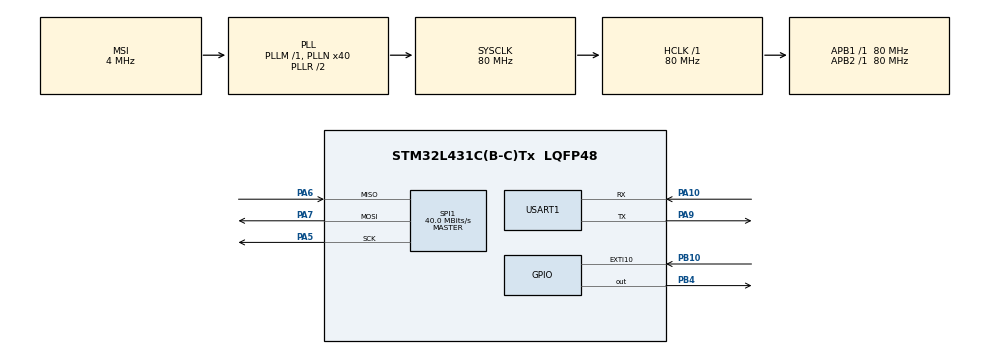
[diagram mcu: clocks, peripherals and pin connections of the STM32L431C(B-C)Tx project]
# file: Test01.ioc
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FREERTOS.Tasks01=defaultTask,24,128,StartDefaultTask,Default,NULL,Dynamic,NULL,NULL
Mcu.Family=STM32L4
Mcu.Name=STM32L431C(B-C)Tx
Mcu.Package=LQFP48
NVIC.EXTI15_10_IRQn=true\:5\:0\:false\:false\:true\:true\:true\:true\:true
NVIC.PriorityGroup=NVIC_PRIORITYGROUP_4
NVIC.SPI1_IRQn=true\:5\:0\:false\:false\:true\:true\:true\:true\:true
NVIC.TIM7_IRQn=true\:15\:0\:false\:false\:true\:false\:false\:true\:true
NVIC.TimeBase=TIM7_IRQn
NVIC.TimeBaseIP=TIM7
PA10.Mode=Asynchronous
PA10.Signal=USART1_RX
PA5.Mode=Full_Duplex_Master
PA5.Signal=SPI1_SCK
PA6.Mode=Full_Duplex_Master
PA6.Signal=SPI1_MISO
PA7.Mode=Full_Duplex_Master
PA7.Signal=SPI1_MOSI
PA9.Mode=Asynchronous
PA9.Signal=USART1_TX
PB0.Signal=SPI1_NSS
PB10.Signal=GPXTI10
PB4\ (NJTRST).Signal=GPIO_Output
ProjectManager.HeapSize=0x200
ProjectManager.StackSize=0x400
ProjectManager.TargetToolchain=Makefile
RCC.AHBFreq_Value=80000000
RCC.APB1Freq_Value=80000000
RCC.APB1TimFreq_Value=80000000
RCC.APB2Freq_Value=80000000
RCC.APB2TimFreq_Value=80000000
RCC.CortexFreq_Value=80000000
RCC.HCLKFreq_Value=80000000
RCC.HSE_VALUE=8000000
RCC.HSI48_VALUE=48000000
RCC.HSI_VALUE=16000000
RCC.LSE_VALUE=32768
RCC.MSI_VALUE=4000000
RCC.PLLN=40
RCC.SYSCLKFreq_VALUE=80000000
RCC.SYSCLKSource=RCC_SYSCLKSOURCE_PLLCLK
RCC.VCOOutputFreq_Value=160000000
SPI1.CalculateBaudRate=40.0 MBits/s
SPI1.Direction=SPI_DIRECTION_2LINES
SPI1.Mode=SPI_MODE_MASTER
SPI1.VirtualType=VM_MASTER
USART1.VirtualMode-Asynchronous=VM_ASYNC
VP_FREERTOS_VS_CMSIS_V2.Mode=CMSIS_V2
VP_SYS_VS_tim7.Mode=TIM7
board=custom

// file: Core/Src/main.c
/* USER CODE BEGIN Header */
/************************************************************************
*
* FILENAME: 	  main.c
* DATE: 		    28.07.2022
* DESCRIPTION: 	Main application entry
* AUTHOR: 		  Embedded Systems Bunyamin Senel
*
************************************************************************
  * @attention
  *
  * Copyright (c) 2022 STMicroelectronics.
  * All rights reserved.
  *
  * This software is licensed under terms that can be found in the LICENSE file
  * in the root directory of this software component.
  * If no LICENSE file comes with this software, it is provided AS-IS.
  *
  ******************************************************************************
  */
/* USER CODE END Header */
#include "main.h"
#include "cmsis_os.h"

/* USER CODE BEGIN Includes */
#include "log.h"
/* USER CODE END Includes */

 SPI_HandleTypeDef hspi1;

UART_HandleTypeDef huart1;

/* Definitions for defaultTask */
osThreadId_t defaultTaskHandle;
const osThreadAttr_t defaultTask_attributes = {
  .name = "defaultTask",
  .stack_size = 128 * 4,
  .priority = (osPriority_t) osPriorityNormal,
};

void SystemClock_Config(void);
static void MX_GPIO_Init(void);
static void MX_USART1_UART_Init(void);
static void MX_SPI1_Init(void);
void StartDefaultTask(void *argument);

int main(void)
{
  /* USER CODE BEGIN 1 */
  LOG_INFO("test");
  /* USER CODE END 1 */

  /* MCU Configuration--------------------------------------------------------*/

  /* Reset of all peripherals, Initializes the Flash interface and the Systick. */
  HAL_Init();

  /* Configure the system clock */
  SystemClock_Config();

  /* Initialize all configured peripherals */
  MX_GPIO_Init();
  MX_USART1_UART_Init();
  MX_SPI1_Init();

  /* Init scheduler */
  osKernelInitialize();

  /* Create the thread(s) */
  /* creation of defaultTask */
  defaultTaskHandle = osThreadNew(StartDefaultTask, NULL, &defaultTask_attributes);

  /* Start scheduler */
  osKernelStart();

  /* We should never get here as control is now taken by the scheduler */
  /* Infinite loop */
  while (1)
  {

    /* USER CODE BEGIN 3 */
    HAL_GPIO_WritePin(GPIOB,GPIO_PIN_4,GPIO_PIN_SET);
  }
  /* USER CODE END 3 */
}

void SystemClock_Config(void)
{
  RCC_OscInitTypeDef RCC_OscInitStruct = {0};
  RCC_ClkInitTypeDef RCC_ClkInitStruct = {0};

  /** Configure the main internal regulator output voltage
  */
  if (HAL_PWREx_ControlVoltageScaling(PWR_REGULATOR_VOLTAGE_SCALE1) != HAL_OK)
  {
    Error_Handler();
  }

  /** Initializes the RCC Oscillators according to the specified parameters
  * in the RCC_OscInitTypeDef structure.
  */
  RCC_OscInitStruct.OscillatorType = RCC_OSCILLATORTYPE_MSI;
  RCC_OscInitStruct.MSIState = RCC_MSI_ON;
  RCC_OscInitStruct.MSICalibrationValue = 0;
  RCC_OscInitStruct.MSIClockRange = RCC_MSIRANGE_6;
  RCC_OscInitStruct.PLL.PLLState = RCC_PLL_ON;
  RCC_OscInitStruct.PLL.PLLSource = RCC_PLLSOURCE_MSI;
  RCC_OscInitStruct.PLL.PLLM = 1;
  RCC_OscInitStruct.PLL.PLLN = 40;
  RCC_OscInitStruct.PLL.PLLP = RCC_PLLP_DIV7;
  RCC_OscInitStruct.PLL.PLLQ = RCC_PLLQ_DIV2;
  RCC_OscInitStruct.PLL.PLLR = RCC_PLLR_DIV2;
  if (HAL_RCC_OscConfig(&RCC_OscInitStruct) != HAL_OK)
  {
    Error_Handler();
  }

  /** Initializes the CPU, AHB and APB buses clocks
  */
  RCC_ClkInitStruct.ClockType = RCC_CLOCKTYPE_HCLK|RCC_CLOCKTYPE_SYSCLK
                              |RCC_CLOCKTYPE_PCLK1|RCC_CLOCKTYPE_PCLK2;
  RCC_ClkInitStruct.SYSCLKSource = RCC_SYSCLKSOURCE_PLLCLK;
  RCC_ClkInitStruct.AHBCLKDivider = RCC_SYSCLK_DIV1;
  RCC_ClkInitStruct.APB1CLKDivider = RCC_HCLK_DIV1;
  RCC_ClkInitStruct.APB2CLKDivider = RCC_HCLK_DIV1;

  if (HAL_RCC_ClockConfig(&RCC_ClkInitStruct, FLASH_LATENCY_4) != HAL_OK)
  {
    Error_Handler();
  }
}

static void MX_SPI1_Init(void)
{

  /* SPI1 parameter configuration*/
  hspi1.Instance = SPI1;
  hspi1.Init.Mode = SPI_MODE_MASTER;
  hspi1.Init.Direction = SPI_DIRECTION_2LINES;
  hspi1.Init.DataSize = SPI_DATASIZE_4BIT;
  hspi1.Init.CLKPolarity = SPI_POLARITY_LOW;
  hspi1.Init.CLKPhase = SPI_PHASE_1EDGE;
  hspi1.Init.NSS = SPI_NSS_SOFT;
  hspi1.Init.BaudRatePrescaler = SPI_BAUDRATEPRESCALER_2;
  hspi1.Init.FirstBit = SPI_FIRSTBIT_MSB;
  hspi1.Init.TIMode = SPI_TIMODE_DISABLE;
  hspi1.Init.CRCCalculation = SPI_CRCCALCULATION_DISABLE;
  hspi1.Init.CRCPolynomial = 7;
  hspi1.Init.CRCLength = SPI_CRC_LENGTH_DATASIZE;
  hspi1.Init.NSSPMode = SPI_NSS_PULSE_ENABLE;
  if (HAL_SPI_Init(&hspi1) != HAL_OK)
  {
    Error_Handler();
  }

}

static void MX_USART1_UART_Init(void)
{

  huart1.Instance = USART1;
  huart1.Init.BaudRate = 115200;
  huart1.Init.WordLength = UART_WORDLENGTH_8B;
  huart1.Init.StopBits = UART_STOPBITS_1;
  huart1.Init.Parity = UART_PARITY_NONE;
  huart1.Init.Mode = UART_MODE_TX_RX;
  huart1.Init.HwFlowCtl = UART_HWCONTROL_NONE;
  huart1.Init.OverSampling = UART_OVERSAMPLING_16;
  huart1.Init.OneBitSampling = UART_ONE_BIT_SAMPLE_DISABLE;
  huart1.AdvancedInit.AdvFeatureInit = UART_ADVFEATURE_NO_INIT;
  if (HAL_UART_Init(&huart1) != HAL_OK)
  {
    Error_Handler();
  }

}

static void MX_GPIO_Init(void)
{
  GPIO_InitTypeDef GPIO_InitStruct = {0};

  /* GPIO Ports Clock Enable */
  __HAL_RCC_GPIOA_CLK_ENABLE();
  __HAL_RCC_GPIOB_CLK_ENABLE();

  /*Configure GPIO pin Output Level */
  HAL_GPIO_WritePin(GPIOB, GPIO_PIN_4, GPIO_PIN_RESET);

  /*Configure GPIO pin : PB10 */
  GPIO_InitStruct.Pin = GPIO_PIN_10;
  GPIO_InitStruct.Mode = GPIO_MODE_IT_RISING;
  GPIO_InitStruct.Pull = GPIO_NOPULL;
  HAL_GPIO_Init(GPIOB, &GPIO_InitStruct);

  /*Configure GPIO pin : PB4 */
  GPIO_InitStruct.Pin = GPIO_PIN_4;
  GPIO_InitStruct.Mode = GPIO_MODE_OUTPUT_PP;
  GPIO_InitStruct.Pull = GPIO_NOPULL;
  GPIO_InitStruct.Speed = GPIO_SPEED_FREQ_LOW;
  HAL_GPIO_Init(GPIOB, &GPIO_InitStruct);

  /* EXTI interrupt init*/
  HAL_NVIC_SetPriority(EXTI15_10_IRQn, 5, 0);
  HAL_NVIC_EnableIRQ(EXTI15_10_IRQn);

}

void StartDefaultTask(void *argument)
{
  for(;;)
  {
    osDelay(1);
  }
}

void HAL_TIM_PeriodElapsedCallback(TIM_HandleTypeDef *htim)
{
  if (htim->Instance == TIM7) {
    HAL_IncTick();
  }
}

void Error_Handler(void)
{
  __disable_irq();
  while (1)
  {
  }
}
